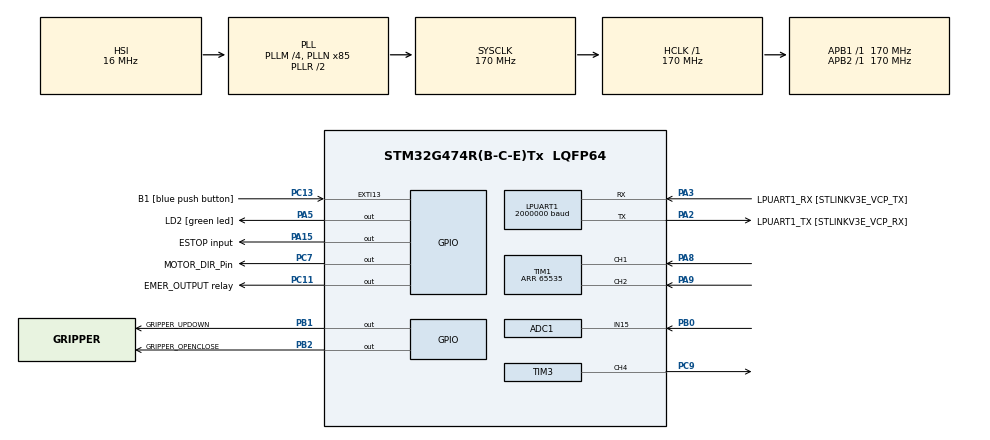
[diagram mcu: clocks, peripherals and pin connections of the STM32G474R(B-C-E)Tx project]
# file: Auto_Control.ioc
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ADC1.Channel-1\#ChannelRegularConversion=ADC_CHANNEL_15
ADC1.NbrOfConversionFlag=1
ADC1.OffsetNumber-1\#ChannelRegularConversion=ADC_OFFSET_NONE
ADC1.Rank-1\#ChannelRegularConversion=1
ADC1.SamplingTime-1\#ChannelRegularConversion=ADC_SAMPLETIME_2CYCLES_5
ADC1.master=1
ARM.CMSIS.5.7.0.CMSISJjCORE=true
ARM.CMSIS.5.7.0.CMSISJjDSP=Library
LPUART1.BaudRate=2000000
Mcu.Family=STM32G4
Mcu.Name=STM32G474R(B-C-E)Tx
Mcu.Package=LQFP64
NVIC.EXTI15_10_IRQn=true\:0\:0\:false\:false\:true\:true\:true\:true
NVIC.PriorityGroup=NVIC_PRIORITYGROUP_4
NVIC.TIM6_DAC_IRQn=true\:0\:0\:false\:false\:true\:true\:true\:true
NVIC.TIM7_DAC_IRQn=true\:0\:0\:false\:false\:true\:true\:true\:true
PA1.Signal=SharedAnalog_PA1
PA13.GPIO_Label=T_SWDIO
PA13.Signal=SYS_JTMS-SWDIO
PA14.GPIO_Label=T_SWCLK
PA14.Signal=SYS_JTCK-SWCLK
PA15.GPIO_Label=ESTOP input
PA15.Signal=GPIO_Output
PA2.GPIO_Label=LPUART1_TX [STLINKV3E_VCP_RX]
PA2.Mode=Asynchronous
PA2.Signal=LPUART1_TX
PA3.GPIO_Label=LPUART1_RX [STLINKV3E_VCP_TX]
PA3.Mode=Asynchronous
PA3.Signal=LPUART1_RX
PA5.GPIO_Label=LD2 [green led]
PA5.Signal=GPIO_Output
PA8.Signal=S_TIM1_CH1
PA9.Signal=S_TIM1_CH2
PB0.Mode=IN15-Single-Ended
PB0.Signal=ADC1_IN15
PB1.GPIO_Label=GRIPPER_UPDOWN
PB1.Signal=GPIO_Output
PB2.GPIO_Label=GRIPPER_OPENCLOSE
PB2.Signal=GPIO_Output
PB3.GPIO_Label=T_SWO
PB3.Signal=SYS_JTDO-SWO
PC11.GPIO_Label=EMER_OUTPUT relay
PC11.Signal=GPIO_Output
PC13.GPIO_Label=B1 [blue push button]
PC13.Signal=GPXTI13
PC14-OSC32_IN.GPIO_Label=RCC_OSC32_IN
PC14-OSC32_IN.Signal=RCC_OSC32_IN
PC15-OSC32_OUT.GPIO_Label=RCC_OSC32_OUT
PC15-OSC32_OUT.Signal=RCC_OSC32_OUT
PC7.GPIO_Label=MOTOR_DIR_Pin
PC7.Signal=GPIO_Output
PC9.Signal=S_TIM3_CH4
PF0-OSC_IN.GPIO_Label=RCC_OSC_IN
PF0-OSC_IN.Signal=RCC_OSC_IN
PF1-OSC_OUT.GPIO_Label=RCC_OSC_OUT
PF1-OSC_OUT.Signal=RCC_OSC_OUT
ProjectManager.HeapSize=0x200
ProjectManager.StackSize=0x400
ProjectManager.TargetToolchain=STM32CubeIDE
RCC.ADC12Freq_Value=170000000
RCC.ADC345Freq_Value=170000000
RCC.AHBFreq_Value=170000000
RCC.APB1Freq_Value=170000000
RCC.APB1TimFreq_Value=170000000
RCC.APB2Freq_Value=170000000
RCC.APB2TimFreq_Value=170000000
RCC.CortexFreq_Value=170000000
RCC.EXTERNAL_CLOCK_VALUE=12288000
RCC.HCLKFreq_Value=170000000
RCC.HSE_VALUE=24000000
RCC.HSI48_VALUE=48000000
RCC.HSI_VALUE=16000000
RCC.LSE_VALUE=32768
RCC.PLLM=RCC_PLLM_DIV4
RCC.PLLN=85
RCC.RTCClockSelection=RCC_RTCCLKSOURCE_LSE
RCC.SYSCLKFreq_VALUE=170000000
RCC.SYSCLKSource=RCC_SYSCLKSOURCE_PLLCLK
RCC.USBFreq_Value=170000000
RCC.VCOOutputFreq_Value=340000000
SH.S_TIM1_CH1.0=TIM1_CH1,Encoder_Interface
SH.S_TIM1_CH2.0=TIM1_CH2,Encoder_Interface
SH.S_TIM3_CH4.0=TIM3_CH4,PWM Generation4 CH4
SH.SharedAnalog_PA1.0=ADC2_IN2
SH.SharedAnalog_PA1.1=ADC1_IN2
TIM1.EncoderMode=TIM_ENCODERMODE_TI12
TIM1.PeriodNoDither=65535
TIM3.Channel-PWM\ Generation4\ CH4=TIM_CHANNEL_4
TIM3.PeriodNoDither=999
TIM3.Prescaler=169
TIM6.PeriodNoDither=999
TIM6.Prescaler=167
TIM7.PeriodNoDither=1999
TIM7.Prescaler=169
VP_ARM.CMSIS_VS_CMSISJjCORE_5.4.0_5.7.0.Mode=CMSISJjCORE
VP_ARM.CMSIS_VS_CMSISJjDSP_1.8.0_5.7.0.Mode=CMSISJjDSP
VP_SYS_VS_DBSignals.Mode=DisableDeadBatterySignals
VP_TIM3_VS_ClockSourceINT.Mode=Internal
VP_TIM6_VS_ClockSourceINT.Mode=Enable_Timer
VP_TIM7_VS_ClockSourceINT.Mode=Enable_Timer
board=NUCLEO-G474RE

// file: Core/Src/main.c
/* USER CODE BEGIN Header */
/**
  ******************************************************************************
  * @file           : main.c
  * @brief          : Main program body
  ******************************************************************************
  * @attention
  *
  * Copyright (c) 2026 STMicroelectronics.
  * All rights reserved.
  *
  * This software is licensed under terms that can be found in the LICENSE file
  * in the root directory of this software component.
  * If no LICENSE file comes with this software, it is provided AS-IS.
  *
  ******************************************************************************
  */
/* USER CODE END Header */
#include "main.h"

/* USER CODE BEGIN Includes */
#include "scurve.h"
#include "encoder.h"
#include "trapezoid.h"
#include "REF_FEEDFORWARD.h"
#include "Kalman4.h"
#include "DistFF.h"
#include <string.h>
#include <math.h>
/* USER CODE END Includes */

/* USER CODE BEGIN PD */
#define LOOP_DT      0.001f    // 1000Hz = 1ms
// max_velocity, max_accel, max_jerk are now volatile floats in Private Variables
// so they can be changed in Live Expressions without reflashing.

// --- Control Mode Constants (set control_mode via Live Expressions) ---
//   1 = Traj FF (open-loop)   — trajectory → RefFF → PWM, no feedback PID
//   2 = Position PID only     — trajectory + position PID → PWM directly (no velocity inner loop)
//   3 = Full cascade          — trajectory + position PID + velocity PID
//   7 = Kalman4 calibration   — direct PWM via kf_cal_pwm + Kalman4 estimation for noise tuning
#define MODE_TRAJ_FF        1
#define MODE_POS_CTRL       2
#define MODE_CASCADE_CTRL   3
#define MODE_KALMAN_CAL     7

// --- Trajectory Type Constants (set traj_type via Live Expressions) ---
//   0 = S-Curve  (jerk-limited, smooth)
//   1 = Trapezoidal  (acceleration-limited, linear ramp)
#define TRAJ_SCURVE      0
#define TRAJ_TRAPEZOID   1

#define DEG_TO_RAD           (3.14159265f / 180.0f) // Degree → radian conversion
#define POS_DT               0.002f                 // 500 Hz position loop (TIM7)
#define TRAJ_DT              0.001f                 // 1000 Hz trajectory generation (TIM6)
#define KF_EXP_COUNT         6                      // number of parallel Kalman instances in Q/R experiment
/* USER CODE END PD */

ADC_HandleTypeDef hadc1;

UART_HandleTypeDef hlpuart1;

TIM_HandleTypeDef htim1;
TIM_HandleTypeDef htim3;
TIM_HandleTypeDef htim6;
TIM_HandleTypeDef htim7;

/* USER CODE BEGIN PV */
SCurve_t        my_scurve;
Trapezoid_t     my_trapezoid;
Encoder_t       my_encoder;
RefFF_t         my_refff;
KalmanFilter4_t my_kf4;
DistFF_t        my_distff;

// --- Trajectory profile limits (Live Expressions — takes effect on next start_move) ---
volatile float max_velocity = 3.0f;   // rad/s   — peak speed of the velocity profile
volatile float max_accel    = 12.56f;   // rad/s²  — max acceleration / deceleration rate
volatile float max_jerk     = 10.0f;   // rad/s³  — S-curve only: rate of accel change

// --- Live Expressions variables ---
// Change these in STM32CubeIDE Live Expressions during debug to switch
// mode or trajectory type without reflashing.
//
//   control_mode : 1 = Traj FF (open-loop),  3 = Full cascade (PID)
//   traj_type    : 0 = S-Curve,   1 = Trapezoidal
volatile uint8_t control_mode      = 3;
volatile uint8_t prev_control_mode = 0xFF;
volatile uint8_t traj_type         = TRAJ_SCURVE;
volatile uint8_t prev_traj_type    = 0xFF;

// Trajectory trigger — set to 1 in Live Expressions to (re)start a move
volatile uint8_t start_move          = 0;

// --- Sequence mode: execute up to 9 preset targets in order ---
volatile float   seq_targets[9]  = {0.0f, 0.0f, 0.0f, 0.0f, 0.0f, 0.0f, 0.0f, 0.0f, 0.0f};
volatile uint8_t seq_count       = 0;    // number of active steps (1-9)
volatile uint8_t seq_enabled     = 0;    // write 1 to start sequence — self-clears when done
volatile uint8_t seq_index       = 0;    // read-only: current step (0-based)
volatile float   seq_step_delay  = 2.0f; // dwell time between steps (s)

// --- Sweep mode: 0 → start → 0 → (start+step) → ... → 0 → stop ---
// Programmatic version of sequence for large step counts.
// Pattern: return to zero between every target, advancing by sweep_step_deg each cycle.
volatile uint8_t sweep_enabled   = 0;      // write 1 to start — self-clears when done
volatile float   sweep_start_deg = 5.0f;   // first non-zero target (deg)
volatile float   sweep_stop_deg  = 360.0f; // last non-zero target (deg)
volatile float   sweep_step_deg  = 5.0f;   // increment per step (deg)
volatile float   sweep_delay_s   = 2.0f;   // dwell time at each position (s)
volatile uint8_t sweep_index     = 0;      // current step index — read-only

// Encoder zero — set to 1 in Live Expressions to zero position at any time
volatile uint8_t zero_encoder        = 0;

// Full state reset — set to 1 to clear ALL runtime state (PIDs, trajectory,
// encoder, commands, observables). Motor stops immediately. Self-clears to 0.
volatile uint8_t reset_all           = 0;

// PID master enable — set to 0 to freeze all PID loops and hold PWM=0.
// Trajectory is paused (does not advance). Set back to 1 to resume control.
// Use start_move=1 after re-enabling to restart the trajectory from scratch.
volatile uint8_t pid_enabled         = 0;

// Target position in DEGREES — type any value here in Live Expressions.
// Changing this automatically starts a new trajectory (no need for start_move).
volatile float   traj_target_deg      = 0.0f;   // target position (deg) — change in Live Expressions
volatile float   prev_traj_target_deg = 0.0f;

// Mode 2 (Position PID only) direct setpoint — no trajectory, just a single degree value.
// Change this in Live Expressions; the position PID tracks it directly.
volatile float   pos_ctrl_target_deg  = 0.0f;

// --- Time-based profile shape parameters (Live Expressions) ---
// S-curve:   t1_seg, t2_seg — ramp shape. t_cruise_seg auto-computed (read-only).
// Trapezoid: t_acc_seg, t_cruise_seg, t_dec_seg — all user-specified (writable).
//            v_peak is back-computed from displacement and times.
//            v_peak is only clamped to max_velocity if it exceeds it.
volatile float   t1_seg            = 0.3f;  // S-curve:   jerk segment duration      (s)
volatile float   t2_seg            = 0.3f;  // S-curve:   const-accel duration       (s)
volatile float   t_acc_seg         = 0.3f;  // Trapezoid: acceleration duration      (s)
volatile float   t_cruise_seg      = 0.5f;  // Trapezoid: cruise duration — writable (s) | S-curve: read-only computed
volatile float   t_dec_seg         = 0.3f;  // Trapezoid: deceleration duration      (s)
// Minimum peak velocity — auto-scales t1/t2 down for short moves so motor
// always ramps fast enough to overcome static friction.  0 = disabled.
volatile float   min_vpeak_rad_s   = 0.5f;  // minimum v_peak (rad/s) — tune up if still jerky

// Telemetry signals — volatile so Live Expressions always reads current RAM value
// UART packet (32 bytes): [0x7E][0x7E][traj_pos][traj_vel][traj_accel][traj_jerk][act_pos][act_vel][kf_vel][0x03][0x03]
//   traj_pos   — absolute trajectory position (rad): traj_start_pos + p_current
//   traj_vel   — trajectory velocity  (rad/s): v_current
//   traj_accel — trajectory accel     (rad/s²): a_current
//   traj_jerk  — trajectory jerk      (rad/s³): j_current  (0 for trapezoid)
//   act_pos    — actual encoder position (rad): my_encoder.position_rad
//   act_vel    — actual encoder velocity (rad/s): my_encoder.velocity_rad_s
//   kf_vel     — Kalman estimated velocity (rad/s): g_kf_velocity
volatile float   g_traj_pos     = 0.0f;  // trajectory absolute position (rad)
volatile float   g_smooth_vel   = 0.0f;  // trajectory velocity          (rad/s)
volatile float   g_smooth_accel = 0.0f;  // trajectory acceleration      (rad/s²)
volatile float   g_jerk         = 0.0f;  // trajectory jerk              (rad/s³)
volatile uint8_t g_traj_active  = 0;     // 1 = trajectory running — written by TIM6 at 1 kHz

// Encoder observables — also in UART packet (act_pos @ byte 18, act_vel @ byte 22)
volatile float g_position_rad   = 0.0f;
volatile float g_velocity_rad_s = 0.0f;
volatile float g_pwm_duty       = 0.0f;

static   uint8_t          tx_buf[76];
volatile uint8_t          tx_pending = 0;

// --- Mode 4: Encoder test — dedicated read-only monitoring variables ---

// --- Motor direction --- set to 1 if actual motion is opposite to trajectory
// Flip in Live Expressions (0 or 1) — takes effect immediately, no reflash needed.
volatile uint8_t motor_dir_inverted = 0;

// --- Emergency output relay (PC11 / EMER_OUTPUT_relay_Pin) ---
// Write 1 to energise the relay, 0 to de-energise.
// Applied every while(1) iteration — no reflash needed.
volatile uint8_t emer_output        = 0;
volatile uint8_t gripper_updown     = 0;   // PB1: 0=down,  1=up
volatile uint8_t gripper_openclose  = 0;   // PB2: 0=close, 1=open

// --- Minimum PWM threshold — overcomes motor static friction (dead zone) ---
// Any non-zero PWM command below this value is raised to this threshold.
// Find your motor's dead zone: increase slowly until the shaft just barely moves.
volatile float min_pwm_threshold = 5.0f;   // % — tune in Live Expressions

// --- PID debug observables (all modes) ---
volatile float ss_error_deg   = 0.0f;  // steady-state position error (degrees)
volatile float ss_error_rad   = 0.0f;  // steady-state position error (radians)
volatile float vel_error_live = 0.0f;  // current velocity error into PID (rad/s)
volatile float i_term_live    = 0.0f;  // current integral accumulator value

// Absolute encoder position captured when a trajectory starts.
// p_current (relative, starts at 0) + traj_start_pos = absolute ideal position.
static float traj_start_pos = 0.0f;

// --- Inter-loop interface: TIM7 (500 Hz) writes, TIM6 (1 kHz) reads ---
volatile float   vel_command      = 0.0f;  // velocity set-point for Modes 3, 5
volatile float   pwm_command      = 0.0f;  // direct PWM for Modes 1, 2, 6
volatile uint8_t hard_stop_active = 0;     // 1 = TIM6 sets PWM=0, skips velocity PID

// --- Reference Feedforward ---
// Set refff_enabled = 1 in Live Expressions to activate.
// V_supply must match the actual bus voltage driving the motor driver.
volatile uint8_t refff_enabled = 1;     // 0 = off, 1 = on
volatile float   V_supply      = 24.0f; // motor bus voltage (V)

// --- Disturbance Feedforward ---
// Uses Kalman4 tau_d estimate to pre-cancel load disturbances.
// distff_tau: filter time constant (s) — same role as in RefFF.
// g_distff_pwm: observe before enabling to check output is sane.
volatile uint8_t distff_enabled = 0;      // 0 = off, 1 = active
volatile float   distff_tau     = 0.02f;  // filter time constant (s)
volatile float   g_distff_pwm  = 0.0f;   // PWM addend from DistFF (%) — read-only

// --- Current sensor — ADC1 IN2 (PA1) ---
// Requires ADC1 IN2 enabled in CubeMX (single or continuous, 12-bit, no DMA).
// Conversion:  I = (adc_raw - current_zero_counts) / current_counts_per_amp
volatile float    current_zero_counts    = 2892.7f; // ADC count at zero current — tune in Live Expressions
volatile float    current_counts_per_amp = 86.57f;  // ADC counts per ampere    — tune in Live Expressions
volatile uint32_t adc_raw_current        = 0;       // raw 12-bit count (0–4095) — read-onlyy
volatile float    g_current_A            = 0.0f;    // measured motor current (A) — read-only

// --- Mode 7: Kalman4 calibration ---
// Set kf_cal_pwm to drive the motor open-loop while Kalman4 estimates the state.
// Tune kf4_sigma_v2 / kf4_r_theta, then reset_all = 1 to reinit with new values.
volatile float   kf_cal_pwm      = 0.0f;   // DC offset PWM command -100..+100 %
volatile uint8_t kf_sine_enabled = 0;      // 0 = direct kf_cal_pwm, 1 = sine wave
volatile float   kf_sine_amp     = 20.0f;  // sine amplitude (%)
volatile float   kf_sine_freq    = 1.0f;   // sine frequency (Hz)
volatile float   kf_sine_dir     = 1.0f;   // +1.0 = normal,  -1.0 = reversed direction
volatile float   kf4_sigma_v2    = 0.01f;   // σ_v² — voltage noise variance: Q = G·σ_v²·Gᵀ → Q[2][2] = σ_v²·(Ts/L)²
volatile float   kf4_r_theta     = 1e-7f;  // R[0] — position measurement noise variance

// --- Kalman4 Q/R Experiment — KF_EXP_COUNT parallel instances running simultaneously ---
// Set kalman_exp_enabled = 1 in Live Expressions to activate.
// When active, the normal 76-byte telemetry is replaced by a 128-byte experiment packet.
// Experiment sets:
//   Index 0-2: fix sigma_v2=0.01, vary r_theta = 1e-4 / 1e-7 / 1e-10
//   Index 3-5: fix r_theta=1e-7,  vary sigma_v2 = 1.0 / 0.01 / 1e-5
// kf_exp_set_id: write 0.0 = R-varied set running; 1.0 = Q-varied set (Simulink label only)
volatile uint8_t kalman_exp_enabled = 0;
volatile float   kf_exp_set_id      = 0.0f;
static   uint8_t kf_exp_tx_pending  = 0;
KalmanFilter4_t  kf_exp[KF_EXP_COUNT];
static float     kf_exp_states[KF_EXP_COUNT][4]; // [pos, vel, current, tau_d] per instance
static uint8_t   kf_exp_tx_buf[128];

static const float kf_exp_sigma_v2[KF_EXP_COUNT] = {
    0.01f, 0.01f,  0.01f,  /* fix Q=0.01, vary R: indices 0-2 */
    1.0f,  0.01f,  1e-5f   /* fix R=1e-7, vary Q: indices 3-5 */
};
static const float kf_exp_r_theta[KF_EXP_COUNT] = {
    1e-4f,  1e-7f,  1e-10f, /* fix Q=0.01, vary R: indices 0-2 */
    1e-7f,  1e-7f,  1e-7f   /* fix R=1e-7, vary Q: indices 3-5 */
};
volatile float   g_kf4_position  = 0.0f;   // Kalman4 estimated position  (rad)   — read-only
volatile float   g_kf4_velocity  = 0.0f;   // Kalman4 estimated velocity  (rad/s) — read-only
volatile float   g_kf4_current   = 0.0f;   // Kalman4 estimated current   (A)     — read-only
volatile float   g_kf4_tau_d_obs = 0.0f;   // Kalman4 estimated τ_d        (N·m)   — read-only
volatile uint8_t use_kf4_vel     = 0;      // 0 = raw encoder velocity, 1 = Kalman4 velocity (both PIDs)
volatile float   g_motor_voltage = 0.0f;   // voltage commanded to motor  (V)     — read-only

// --- Motor parameters — change in Live Expressions, then write apply_motor_params=1 ---
// Both Kalman4 and RefFF will be re-initialised with the new values (position not reset).
volatile float   motor_J_eq  = 0.027f;      // kg·m²    — equivalent inertia (at output shaft)
volatile float   motor_b_eq  = 0.5f;        // N·m·s/r  — equivalent viscous friction
volatile float   motor_N     = 50.0f;       // —         — gear ratio
volatile float   motor_Kt    = 0.00747f;    // N·m/A    — torque constant
volatile float   motor_Ke    = 0.0083f;     // V·s/rad  — back-EMF constant
volatile float   motor_L     = 0.0012794f;  // H         — armature inductance
volatile float   motor_R_arm = 2.8f;        // Ω         — armature resistance
volatile uint8_t apply_motor_params = 0;    // write 1 to apply — self-clears
/* USER CODE END PV */

void SystemClock_Config(void);
static void MX_GPIO_Init(void);
static void MX_LPUART1_UART_Init(void);
static void MX_TIM1_Init(void);
static void MX_TIM6_Init(void);
static void MX_TIM3_Init(void);
static void MX_TIM7_Init(void);
static void MX_ADC1_Init(void);
/* USER CODE BEGIN PFP */
extern float Velocity_PID_Controller(float error);
void Set_Motor_PWM(float pwm_duty);
/* USER CODE END PFP */

/* USER CODE BEGIN 0 */
// --- Velocity PID gains (tunable in Live Expressions) ---
// kp_vel sizing: output = kp_vel × vel_error [rad/s]  →  PWM [%]
// Rule: kp_vel = max_pwm / max_velocity = 100 / 1.57 ≈ 64 gives full PWM at max error.
// Start at 30 (≈ half authority) and tune up until motor tracks trajectory cleanly.
// kd_vel stays 0: derivative amplifies quantization noise at 1 kHz.
float kp_vel = 10.0f;
float ki_vel =  0.01f;
float kd_vel =  0.0f;

float vel_integral    = 0.0f;
float vel_prev_error  = 0.0f;
float max_pwm         = 100.0f;

// --- Saturation experiment limits (Live Expressions — change without reflashing) ---
// vel_sat_rad_s  : caps total vel_command (trajectory + PID correction) into velocity PID.
//                  Default = max_velocity. Lower this to observe velocity saturation effect.
// voltage_sat_pct: caps final PWM output after RefFF + DistFF, before Set_Motor_PWM.
//                  Default = 100%. Lower this to observe voltage saturation effect.
volatile float vel_sat_rad_s    = 53.0f;   // rad/s — velocity command saturation
volatile float voltage_sat_pct  = 100.0f;  // %     — voltage/PWM output saturation

// --- Loop frequency experiment (Live Expressions — no reflash needed) ---
// inner_loop_div: velocity PID fires every N TIM6 ticks (1=1kHz, 2=500Hz, 5=200Hz, 10=100Hz)
// outer_loop_div: position PID fires every N TIM7 ticks (1=500Hz, 2=250Hz, 4=125Hz)
// loop_dt_inner/outer are updated automatically by the ISR — do NOT write them manually.
volatile uint8_t inner_loop_div = 1;
volatile uint8_t outer_loop_div = 1;
volatile float   loop_dt_inner  = 0.001f;   // inner_loop_div × LOOP_DT
volatile float   loop_dt_outer  = 0.002f;   // outer_loop_div × POS_DT

// --- Position PID gains — Modes 3 & 5 output: velocity (rad/s) ---
// kp_position: [rad/s] per [rad] of error. Start at 1.0, tune up carefully.
volatile float kp_position       = 2.0f;
volatile float ki_pos            = 0.5f;
volatile float kd_pos            = 0.01f;
volatile float pos_deadband_deg  = 0.1f;
volatile float vel_deadband_rad_s = 0.3f;   // velocity threshold for hard stop (rad/s)
volatile uint8_t  ss_reached       = 1;      // 1 = position error within pos_deadband_deg
volatile float    ss_final_error_deg = 0.0f; // error captured at the moment hard stop fired
volatile float pos_integral_live = 0.0f;

float pos_integral  = 0.0f;

// --- Anti-windup enable flags (toggle in Live Expressions — no reflash needed) ---
// 1 = clamp accumulator (protected), 0 = free accumulation (windup scenario)
volatile uint8_t vel_antiwindup_en = 1;
volatile uint8_t pos_antiwindup_en = 1;

float Velocity_PID_Controller(float error) {
    // Proportional
    float p_out = kp_vel * error;

    // Integral with proper anti-windup:
    // Clamp the ACCUMULATOR itself so i_out can never exceed max_pwm.
    // The old approach only clamped i_out at output but let vel_integral
    // grow without bound — causing the motor to keep running after trajectory ends.
    vel_integral += error * loop_dt_inner;
    if (vel_antiwindup_en) {
        float max_integral = (ki_vel > 0.0f) ? (max_pwm / ki_vel) : 0.0f;
        if (vel_integral >  max_integral) vel_integral =  max_integral;
        if (vel_integral < -max_integral) vel_integral = -max_integral;
    }
    float i_out = ki_vel * vel_integral;

    // Derivative
    float derivative = (error - vel_prev_error) / loop_dt_inner;
    float d_out      = kd_vel * derivative;
    vel_prev_error   = error;

    // Expose internals for Live Expressions debugging
    i_term_live = vel_integral;

    // Total output — clamped to PWM limits
    float output = p_out + i_out + d_out;
    if (output >  max_pwm) output =  max_pwm;
    if (output < -max_pwm) output = -max_pwm;

    return output;
}

void Velocity_PID_Reset(void) {
    vel_integral   = 0.0f;
    vel_prev_error = 0.0f;
}

/* Position PID controller.
 *   pos_error    : target_pos − actual_pos  (radians)
 *   vel_feedback : filtered actual velocity  (rad/s)
 *   returns      : velocity command (rad/s) for Modes 3 & 5
 *                  or PWM duty (%) for Mode 2 — caller applies limits.
 *
 * Derivative term uses −velocity instead of Δerror/dt.
 * Reason: d(pos_error)/dt = −d(actual)/dt = −velocity.
 * Using measured velocity is far less noisy than differencing position error. */
float Position_PID_Controller(float pos_error, float vel_feedback) {
    float p_out = kp_position * pos_error;

    // Integral with anti-windup — clamp accumulator so i_out ≤ max_velocity
    pos_integral += pos_error * loop_dt_outer;
    if (pos_antiwindup_en) {
        float max_pos_int = (ki_pos > 0.0f) ? (max_velocity / ki_pos) : 0.0f;
        if (pos_integral >  max_pos_int) pos_integral =  max_pos_int;
        if (pos_integral < -max_pos_int) pos_integral = -max_pos_int;
    }
    float i_out = ki_pos * pos_integral;
    pos_integral_live = pos_integral;

    // Derivative: negate velocity (= derivative of position error)
    float d_out = -kd_pos * vel_feedback;

    return p_out + i_out + d_out;
}

void Position_PID_Reset(void) {
    pos_integral      = 0.0f;
    pos_integral_live = 0.0f;
}

static void Pack_Telemetry(void) {
    // 72-byte packet:
    //  [0x7E][0x7E]
    //  [2 ] traj_pos     4B  float   trajectory ideal position   (rad)
    //  [6 ] traj_vel     4B  float   trajectory velocity         (rad/s)
    //  [10] traj_accel   4B  float   trajectory acceleration     (rad/s²)
    //  [14] traj_jerk    4B  float   trajectory jerk             (rad/s³)
    //  [18] act_pos      4B  float   actual encoder position     (rad)
    //  [22] act_vel      4B  float   actual encoder velocity     (rad/s)
    //  [26] kf_vel       4B  float   Kalman estimated velocity   (rad/s)
    //  [30] kf_pos       4B  float   Kalman estimated position   (rad)
    //  [34] ss_error     4B  float   steady-state position error (rad)
    //  [38] current      4B  float   measured motor current      (A)
    //  [42] kf4_pos      4B  float   Kalman4 estimated position  (rad)
    //  [46] kf4_vel      4B  float   Kalman4 estimated velocity  (rad/s)
    //  [50] kf4_current  4B  float   Kalman4 estimated current   (A)
    //  [54] kf4_tau_d    4B  float   Kalman4 disturbance torque  (N·m)
    //  [58] voltage      4B  float   motor commanded voltage     (V)
    //  [62] adc_raw      4B  uint32  raw ADC count               (0–4095)
    //  [66] i_term_live       4B  float   velocity integrator accumulator
    //  [70] pos_integral_live 4B  float   position integrator accumulator
    //  [74][0x03][0x03]
    tx_buf[0] = 0x7E;
    tx_buf[1] = 0x7E;
    memcpy(&tx_buf[2],  (const void *)&g_traj_pos,        4);
    memcpy(&tx_buf[6],  (const void *)&g_smooth_vel,      4);
    memcpy(&tx_buf[10], (const void *)&g_smooth_accel,    4);
    memcpy(&tx_buf[14], (const void *)&g_jerk,            4);
    memcpy(&tx_buf[18], (const void *)&g_position_rad,    4);
    memcpy(&tx_buf[22], (const void *)&g_velocity_rad_s,  4);
    memcpy(&tx_buf[26], (const void *)&g_kf4_velocity,    4);
    memcpy(&tx_buf[30], (const void *)&g_kf4_position,    4);
    memcpy(&tx_buf[34], (const void *)&ss_error_rad,      4);
    memcpy(&tx_buf[38], (const void *)&g_current_A,       4);
    memcpy(&tx_buf[42], (const void *)&g_kf4_position,    4);
    memcpy(&tx_buf[46], (const void *)&g_kf4_velocity,    4);
    memcpy(&tx_buf[50], (const void *)&g_kf4_current,     4);
    memcpy(&tx_buf[54], (const void *)&g_kf4_tau_d_obs,   4);
    memcpy(&tx_buf[58], (const void *)&g_motor_voltage,   4);
    memcpy(&tx_buf[62], (const void *)&adc_raw_current,   4);
    memcpy(&tx_buf[66], (const void *)&i_term_live,       4);
    memcpy(&tx_buf[70], (const void *)&pos_integral_live, 4);
    tx_buf[74] = 0x03;
    tx_buf[75] = 0x03;
}

static void KalmanExp_Init(void) {
    for (int n = 0; n < KF_EXP_COUNT; n++) {
        Kalman4_Init(&kf_exp[n],
                     my_encoder.position_rad, 0.0f, 0.0f,
                     LOOP_DT,
                     motor_J_eq, motor_b_eq, motor_N, motor_Kt, motor_Ke,
                     motor_L,    motor_R_arm,
                     kf_exp_sigma_v2[n], kf_exp_r_theta[n]);
    }
}

static void Pack_KalmanExp_Telemetry(void) {
    // 128-byte Kalman experiment packet:
    //  [0-1]    0x7E 0x7E  header (same as normal packet — Waijung uses same framing)
    //  [2 ]     ref_pos     4B  float  trajectory reference position  (rad)
    //  [6 ]     ref_vel     4B  float  trajectory reference velocity  (rad/s)
    //  [10]     real_pos    4B  float  encoder position               (rad)
    //  [14]     real_vel    4B  float  encoder velocity               (rad/s)
    //  [18]     current_A   4B  float  motor current                  (A)
    //  [22]     voltage     4B  float  motor voltage                  (V)
    //  [26]     set_id      4B  float  0=vary-R experiment, 1=vary-Q  (label)
    //  [30..45]  kf[0]  pos, vel, current, tau_d  (4×4B = 16B)
    //  [46..61]  kf[1]  pos, vel, current, tau_d
    //  [62..77]  kf[2]  pos, vel, current, tau_d
    //  [78..93]  kf[3]  pos, vel, current, tau_d
    //  [94..109] kf[4]  pos, vel, current, tau_d
    //  [110..125]kf[5]  pos, vel, current, tau_d
    //  [126][127] 0x03 0x03  footer
    kf_exp_tx_buf[0] = 0x7E;
    kf_exp_tx_buf[1] = 0x7E;
    memcpy(&kf_exp_tx_buf[2],  (const void *)&g_traj_pos,        4);
    memcpy(&kf_exp_tx_buf[6],  (const void *)&g_smooth_vel,      4);
    memcpy(&kf_exp_tx_buf[10], (const void *)&g_position_rad,    4);
    memcpy(&kf_exp_tx_buf[14], (const void *)&g_velocity_rad_s,  4);
    memcpy(&kf_exp_tx_buf[18], (const void *)&g_current_A,       4);
    memcpy(&kf_exp_tx_buf[22], (const void *)&g_motor_voltage,   4);
    memcpy(&kf_exp_tx_buf[26], (const void *)&kf_exp_set_id,     4);
    for (int n = 0; n < KF_EXP_COUNT; n++) {
        uint16_t off = (uint16_t)(30 + n * 16);
        memcpy(&kf_exp_tx_buf[off],      &kf_exp_states[n][0], 4);
        memcpy(&kf_exp_tx_buf[off +  4], &kf_exp_states[n][1], 4);
        memcpy(&kf_exp_tx_buf[off +  8], &kf_exp_states[n][2], 4);
        memcpy(&kf_exp_tx_buf[off + 12], &kf_exp_states[n][3], 4);
    }
    kf_exp_tx_buf[126] = 0x03;
    kf_exp_tx_buf[127] = 0x03;
}

/* USER CODE END 0 */

int main(void)
{

  /* MCU Configuration--------------------------------------------------------*/

  /* Reset of all peripherals, Initializes the Flash interface and the Systick. */
  HAL_Init();

  /* Configure the system clock */
  SystemClock_Config();

  /* Initialize all configured peripherals */
  MX_GPIO_Init();
  MX_LPUART1_UART_Init();
  MX_TIM1_Init();
  MX_TIM6_Init();
  MX_TIM3_Init();
  MX_TIM7_Init();
  MX_ADC1_Init();
  /* USER CODE BEGIN 2 */
  // 1. Initialize trajectory and profile math (POS_DT: trajectory runs in 500 Hz TIM7 loop)
      SCurve_Init(&my_scurve, max_velocity, max_accel, max_jerk, TRAJ_DT);
      Trapezoid_Init(&my_trapezoid, max_velocity, max_accel, TRAJ_DT);

      // Reference feedforward — fill in your motor parameters before enabling.
      // refff_enabled = 0 at startup; set to 1 in Live Expressions to activate.
      RefFF_Init(&my_refff,
                 /* J_eq  */ motor_J_eq,
                 /* L     */ motor_L,
                 /* R     */ motor_R_arm,
                 /* b_eq  */ motor_b_eq,
                 /* N     */ motor_N,
                 /* Kt    */ motor_Kt,
                 /* Ke    */ motor_Ke,
                 /* tau   */ 0.02f,
                 /* Ts    */ LOOP_DT
      );

      DistFF_Init(&my_distff,
                  /* L   */ motor_L,
                  /* R   */ motor_R_arm,
                  /* N   */ motor_N,
                  /* Kt  */ motor_Kt,
                  /* tau */ distff_tau,
                  /* Ts  */ LOOP_DT);

      // Kalman4 — 4-state motor filter (position-only measurement, no current sensor).
      // Motor parameters match RefFF_Init above. Tune kf4_* noise params in Live Expressions,
      // then set reset_all = 1 to reinitialise with the new values.
      Kalman4_Init(&my_kf4,
                   /* theta0, omega0, i0 */ 0.0f, 0.0f, 0.0f,
                   /* Ts     */ LOOP_DT,
                   /* J_eq   */ motor_J_eq,
                   /* b_eq   */ motor_b_eq,
                   /* N      */ motor_N,
                   /* Kt     */ motor_Kt,
                   /* Ke     */ motor_Ke,
                   /* L      */ motor_L,
                   /* R_arm  */ motor_R_arm,
                   /* sigma_v2  */ kf4_sigma_v2,
                   /* r_theta   */ kf4_r_theta);
      KalmanExp_Init();

      // 2. Start TIM1 encoder, zero its counter, THEN init encoder struct.
      //    Order matters: counter must be zeroed before Encoder_Init reads
      //    last_counter_value = 0, so the first delta is always 0.
      HAL_TIM_Encoder_Start(&htim1, TIM_CHANNEL_ALL);
      __HAL_TIM_SET_COUNTER(&htim1, 0);
      Encoder_Init(&my_encoder, LOOP_DT);

      // 3. Start TIM3 PWM output
      HAL_TIM_PWM_Start(&htim3, TIM_CHANNEL_4);

      // 4. Start TIM7 (500 Hz position loop) then TIM6 (1 kHz velocity loop)
      MX_TIM7_Init();
      HAL_TIM_Base_Start_IT(&htim7);
      HAL_TIM_Base_Start_IT(&htim6);

      // 5. ADC1 current sensor (PA1 / IN2) — first conversion started by ISR.
  /* USER CODE END 2 */

  /* Infinite loop */
  while (1)
  {

    /* USER CODE BEGIN 3 */
      if (kf_exp_tx_pending) {
          kf_exp_tx_pending = 0;
          HAL_UART_Transmit(&hlpuart1, kf_exp_tx_buf, sizeof(kf_exp_tx_buf), 5);
      } else if (tx_pending) {
          tx_pending = 0;
          HAL_UART_Transmit(&hlpuart1, tx_buf, sizeof(tx_buf), 2);
      }
      HAL_GPIO_WritePin(EMER_OUTPUT_relay_GPIO_Port, EMER_OUTPUT_relay_Pin,
                        emer_output ? GPIO_PIN_SET : GPIO_PIN_RESET);
      HAL_GPIO_WritePin(GRIPPER_UPDOWN_GPIO_Port, GRIPPER_UPDOWN_Pin,
                        gripper_updown    ? GPIO_PIN_SET : GPIO_PIN_RESET);
      HAL_GPIO_WritePin(GRIPPER_OPENCLOSE_GPIO_Port, GRIPPER_OPENCLOSE_Pin,
                        gripper_openclose ? GPIO_PIN_SET : GPIO_PIN_RESET);
  }
  /* USER CODE END 3 */
}

void SystemClock_Config(void)
{
  RCC_OscInitTypeDef RCC_OscInitStruct = {0};
  RCC_ClkInitTypeDef RCC_ClkInitStruct = {0};

  /** Configure the main internal regulator output voltage
  */
  HAL_PWREx_ControlVoltageScaling(PWR_REGULATOR_VOLTAGE_SCALE1_BOOST);

  /** Initializes the RCC Oscillators according to the specified parameters
  * in the RCC_OscInitTypeDef structure.
  */
  RCC_OscInitStruct.OscillatorType = RCC_OSCILLATORTYPE_HSI;
  RCC_OscInitStruct.HSIState = RCC_HSI_ON;
  RCC_OscInitStruct.HSICalibrationValue = RCC_HSICALIBRATION_DEFAULT;
  RCC_OscInitStruct.PLL.PLLState = RCC_PLL_ON;
  RCC_OscInitStruct.PLL.PLLSource = RCC_PLLSOURCE_HSI;
  RCC_OscInitStruct.PLL.PLLM = RCC_PLLM_DIV4;
  RCC_OscInitStruct.PLL.PLLN = 85;
  RCC_OscInitStruct.PLL.PLLP = RCC_PLLP_DIV2;
  RCC_OscInitStruct.PLL.PLLQ = RCC_PLLQ_DIV2;
  RCC_OscInitStruct.PLL.PLLR = RCC_PLLR_DIV2;
  if (HAL_RCC_OscConfig(&RCC_OscInitStruct) != HAL_OK)
  {
    Error_Handler();
  }

  /** Initializes the CPU, AHB and APB buses clocks
  */
  RCC_ClkInitStruct.ClockType = RCC_CLOCKTYPE_HCLK|RCC_CLOCKTYPE_SYSCLK
                              |RCC_CLOCKTYPE_PCLK1|RCC_CLOCKTYPE_PCLK2;
  RCC_ClkInitStruct.SYSCLKSource = RCC_SYSCLKSOURCE_PLLCLK;
  RCC_ClkInitStruct.AHBCLKDivider = RCC_SYSCLK_DIV1;
  RCC_ClkInitStruct.APB1CLKDivider = RCC_HCLK_DIV1;
  RCC_ClkInitStruct.APB2CLKDivider = RCC_HCLK_DIV1;

  if (HAL_RCC_ClockConfig(&RCC_ClkInitStruct, FLASH_LATENCY_4) != HAL_OK)
  {
    Error_Handler();
  }
}

static void MX_ADC1_Init(void)
{

  ADC_MultiModeTypeDef multimode = {0};
  ADC_ChannelConfTypeDef sConfig = {0};

  /** Common config
  */
  hadc1.Instance = ADC1;
  hadc1.Init.ClockPrescaler = ADC_CLOCK_SYNC_PCLK_DIV4;
  hadc1.Init.Resolution = ADC_RESOLUTION_12B;
  hadc1.Init.DataAlign = ADC_DATAALIGN_RIGHT;
  hadc1.Init.GainCompensation = 0;
  hadc1.Init.ScanConvMode = ADC_SCAN_DISABLE;
  hadc1.Init.EOCSelection = ADC_EOC_SINGLE_CONV;
  hadc1.Init.LowPowerAutoWait = DISABLE;
  hadc1.Init.ContinuousConvMode = DISABLE;
  hadc1.Init.NbrOfConversion = 1;
  hadc1.Init.DiscontinuousConvMode = DISABLE;
  hadc1.Init.ExternalTrigConv = ADC_SOFTWARE_START;
  hadc1.Init.ExternalTrigConvEdge = ADC_EXTERNALTRIGCONVEDGE_NONE;
  hadc1.Init.DMAContinuousRequests = DISABLE;
  hadc1.Init.Overrun = ADC_OVR_DATA_PRESERVED;
  hadc1.Init.OversamplingMode = DISABLE;
  if (HAL_ADC_Init(&hadc1) != HAL_OK)
  {
    Error_Handler();
  }

  /** Configure the ADC multi-mode
  */
  multimode.Mode = ADC_MODE_INDEPENDENT;
  if (HAL_ADCEx_MultiModeConfigChannel(&hadc1, &multimode) != HAL_OK)
  {
    Error_Handler();
  }

  /** Configure Regular Channel
  */
  sConfig.Channel = ADC_CHANNEL_15;
  sConfig.Rank = ADC_REGULAR_RANK_1;
  sConfig.SamplingTime = ADC_SAMPLETIME_2CYCLES_5;
  sConfig.SingleDiff = ADC_SINGLE_ENDED;
  sConfig.OffsetNumber = ADC_OFFSET_NONE;
  sConfig.Offset = 0;
  if (HAL_ADC_ConfigChannel(&hadc1, &sConfig) != HAL_OK)
  {
    Error_Handler();
  }

}

static void MX_LPUART1_UART_Init(void)
{

  hlpuart1.Instance = LPUART1;
  hlpuart1.Init.BaudRate = 2000000;
  hlpuart1.Init.WordLength = UART_WORDLENGTH_8B;
  hlpuart1.Init.StopBits = UART_STOPBITS_1;
  hlpuart1.Init.Parity = UART_PARITY_NONE;
  hlpuart1.Init.Mode = UART_MODE_TX_RX;
  hlpuart1.Init.HwFlowCtl = UART_HWCONTROL_NONE;
  hlpuart1.Init.OneBitSampling = UART_ONE_BIT_SAMPLE_DISABLE;
  hlpuart1.Init.ClockPrescaler = UART_PRESCALER_DIV1;
  hlpuart1.AdvancedInit.AdvFeatureInit = UART_ADVFEATURE_NO_INIT;
  if (HAL_UART_Init(&hlpuart1) != HAL_OK)
  {
    Error_Handler();
  }
  if (HAL_UARTEx_SetTxFifoThreshold(&hlpuart1, UART_TXFIFO_THRESHOLD_1_8) != HAL_OK)
  {
    Error_Handler();
  }
  if (HAL_UARTEx_SetRxFifoThreshold(&hlpuart1, UART_RXFIFO_THRESHOLD_1_8) != HAL_OK)
  {
    Error_Handler();
  }
  if (HAL_UARTEx_DisableFifoMode(&hlpuart1) != HAL_OK)
  {
    Error_Handler();
  }

}

static void MX_TIM1_Init(void)
{

  TIM_Encoder_InitTypeDef sConfig = {0};
  TIM_MasterConfigTypeDef sMasterConfig = {0};

  htim1.Instance = TIM1;
  htim1.Init.Prescaler = 0;
  htim1.Init.CounterMode = TIM_COUNTERMODE_UP;
  htim1.Init.Period = 65535;
  htim1.Init.ClockDivision = TIM_CLOCKDIVISION_DIV1;
  htim1.Init.RepetitionCounter = 0;
  htim1.Init.AutoReloadPreload = TIM_AUTORELOAD_PRELOAD_DISABLE;
  sConfig.EncoderMode = TIM_ENCODERMODE_TI12;
  sConfig.IC1Polarity = TIM_ICPOLARITY_RISING;
  sConfig.IC1Selection = TIM_ICSELECTION_DIRECTTI;
  sConfig.IC1Prescaler = TIM_ICPSC_DIV1;
  sConfig.IC1Filter = 0;
  sConfig.IC2Polarity = TIM_ICPOLARITY_RISING;
  sConfig.IC2Selection = TIM_ICSELECTION_DIRECTTI;
  sConfig.IC2Prescaler = TIM_ICPSC_DIV1;
  sConfig.IC2Filter = 0;
  if (HAL_TIM_Encoder_Init(&htim1, &sConfig) != HAL_OK)
  {
    Error_Handler();
  }
  sMasterConfig.MasterOutputTrigger = TIM_TRGO_RESET;
  sMasterConfig.MasterOutputTrigger2 = TIM_TRGO2_RESET;
  sMasterConfig.MasterSlaveMode = TIM_MASTERSLAVEMODE_DISABLE;
  if (HAL_TIMEx_MasterConfigSynchronization(&htim1, &sMasterConfig) != HAL_OK)
  {
    Error_Handler();
  }

}

static void MX_TIM3_Init(void)
{

  TIM_ClockConfigTypeDef sClockSourceConfig = {0};
  TIM_MasterConfigTypeDef sMasterConfig = {0};
  TIM_OC_InitTypeDef sConfigOC = {0};

  htim3.Instance = TIM3;
  htim3.Init.Prescaler = 169;
  htim3.Init.CounterMode = TIM_COUNTERMODE_UP;
  htim3.Init.Period = 999;
  htim3.Init.ClockDivision = TIM_CLOCKDIVISION_DIV1;
  htim3.Init.AutoReloadPreload = TIM_AUTORELOAD_PRELOAD_DISABLE;
  if (HAL_TIM_Base_Init(&htim3) != HAL_OK)
  {
    Error_Handler();
  }
  sClockSourceConfig.ClockSource = TIM_CLOCKSOURCE_INTERNAL;
  if (HAL_TIM_ConfigClockSource(&htim3, &sClockSourceConfig) != HAL_OK)
  {
    Error_Handler();
  }
  if (HAL_TIM_PWM_Init(&htim3) != HAL_OK)
  {
    Error_Handler();
  }
  sMasterConfig.MasterOutputTrigger = TIM_TRGO_RESET;
  sMasterConfig.MasterSlaveMode = TIM_MASTERSLAVEMODE_DISABLE;
  if (HAL_TIMEx_MasterConfigSynchronization(&htim3, &sMasterConfig) != HAL_OK)
  {
    Error_Handler();
  }
  sConfigOC.OCMode = TIM_OCMODE_PWM1;
  sConfigOC.Pulse = 0;
  sConfigOC.OCPolarity = TIM_OCPOLARITY_HIGH;
  sConfigOC.OCFastMode = TIM_OCFAST_DISABLE;
  if (HAL_TIM_PWM_ConfigChannel(&htim3, &sConfigOC, TIM_CHANNEL_4) != HAL_OK)
  {
    Error_Handler();
  }
  HAL_TIM_MspPostInit(&htim3);

}

static void MX_TIM6_Init(void)
{

  TIM_MasterConfigTypeDef sMasterConfig = {0};

  htim6.Instance = TIM6;
  htim6.Init.Prescaler = 167;
  htim6.Init.CounterMode = TIM_COUNTERMODE_UP;
  htim6.Init.Period = 999;
  htim6.Init.AutoReloadPreload = TIM_AUTORELOAD_PRELOAD_DISABLE;
  if (HAL_TIM_Base_Init(&htim6) != HAL_OK)
  {
    Error_Handler();
  }
  sMasterConfig.MasterOutputTrigger = TIM_TRGO_RESET;
  sMasterConfig.MasterSlaveMode = TIM_MASTERSLAVEMODE_DISABLE;
  if (HAL_TIMEx_MasterConfigSynchronization(&htim6, &sMasterConfig) != HAL_OK)
  {
    Error_Handler();
  }

}

static void MX_TIM7_Init(void)
{

  TIM_MasterConfigTypeDef sMasterConfig = {0};

  htim7.Instance = TIM7;
  htim7.Init.Prescaler = 169;
  htim7.Init.CounterMode = TIM_COUNTERMODE_UP;
  htim7.Init.Period = 1999;
  htim7.Init.AutoReloadPreload = TIM_AUTORELOAD_PRELOAD_DISABLE;
  if (HAL_TIM_Base_Init(&htim7) != HAL_OK)
  {
    Error_Handler();
  }
  sMasterConfig.MasterOutputTrigger = TIM_TRGO_RESET;
  sMasterConfig.MasterSlaveMode = TIM_MASTERSLAVEMODE_DISABLE;
  if (HAL_TIMEx_MasterConfigSynchronization(&htim7, &sMasterConfig) != HAL_OK)
  {
    Error_Handler();
  }

}

static void MX_GPIO_Init(void)
{
  GPIO_InitTypeDef GPIO_InitStruct = {0};

  /* GPIO Ports Clock Enable */
  __HAL_RCC_GPIOC_CLK_ENABLE();
  __HAL_RCC_GPIOF_CLK_ENABLE();
  __HAL_RCC_GPIOA_CLK_ENABLE();
  __HAL_RCC_GPIOB_CLK_ENABLE();

  /*Configure GPIO pin Output Level */
  HAL_GPIO_WritePin(GPIOA, LD2_Pin|ESTOP_input_Pin, GPIO_PIN_RESET);

  /*Configure GPIO pin Output Level */
  HAL_GPIO_WritePin(GPIOB, GRIPPER_UPDOWN_Pin|GRIPPER_OPENCLOSE_Pin, GPIO_PIN_RESET);

  /*Configure GPIO pin Output Level */
  HAL_GPIO_WritePin(GPIOC, MOTOR_DIR_Pin_Pin|EMER_OUTPUT_relay_Pin, GPIO_PIN_RESET);

  /*Configure GPIO pin : B1_Pin */
  GPIO_InitStruct.Pin = B1_Pin;
  GPIO_InitStruct.Mode = GPIO_MODE_IT_RISING;
  GPIO_InitStruct.Pull = GPIO_NOPULL;
  HAL_GPIO_Init(B1_GPIO_Port, &GPIO_InitStruct);

  /*Configure GPIO pin : PA1 */
  GPIO_InitStruct.Pin = GPIO_PIN_1;
  GPIO_InitStruct.Mode = GPIO_MODE_ANALOG;
  GPIO_InitStruct.Pull = GPIO_NOPULL;
  HAL_GPIO_Init(GPIOA, &GPIO_InitStruct);

  /*Configure GPIO pins : LD2_Pin ESTOP_input_Pin */
  GPIO_InitStruct.Pin = LD2_Pin|ESTOP_input_Pin;
  GPIO_InitStruct.Mode = GPIO_MODE_OUTPUT_PP;
  GPIO_InitStruct.Pull = GPIO_NOPULL;
  GPIO_InitStruct.Speed = GPIO_SPEED_FREQ_LOW;
  HAL_GPIO_Init(GPIOA, &GPIO_InitStruct);

  /*Configure GPIO pins : GRIPPER_UPDOWN_Pin GRIPPER_OPENCLOSE_Pin */
  GPIO_InitStruct.Pin = GRIPPER_UPDOWN_Pin|GRIPPER_OPENCLOSE_Pin;
  GPIO_InitStruct.Mode = GPIO_MODE_OUTPUT_PP;
  GPIO_InitStruct.Pull = GPIO_NOPULL;
  GPIO_InitStruct.Speed = GPIO_SPEED_FREQ_LOW;
  HAL_GPIO_Init(GPIOB, &GPIO_InitStruct);

  /*Configure GPIO pins : MOTOR_DIR_Pin_Pin EMER_OUTPUT_relay_Pin */
  GPIO_InitStruct.Pin = MOTOR_DIR_Pin_Pin|EMER_OUTPUT_relay_Pin;
  GPIO_InitStruct.Mode = GPIO_MODE_OUTPUT_PP;
  GPIO_InitStruct.Pull = GPIO_NOPULL;
  GPIO_InitStruct.Speed = GPIO_SPEED_FREQ_LOW;
  HAL_GPIO_Init(GPIOC, &GPIO_InitStruct);

  /* EXTI interrupt init*/
  HAL_NVIC_SetPriority(EXTI15_10_IRQn, 0, 0);
  HAL_NVIC_EnableIRQ(EXTI15_10_IRQn);

}

/* USER CODE BEGIN 4 */
static uint8_t prev_traj_active_m3 = 0;   // Mode 3: detects trajectory completion in TIM7
static uint8_t prev_pid_enabled    = 0;   // rising-edge detector for pid_enabled
static uint8_t  seq_was_enabled     = 0;       // sequence rising-edge detector
static uint8_t  seq_step_done       = 0;       // 1 = step settled, counting delay
static uint32_t seq_delay_counter   = 0;       // TIM7 ticks remaining in inter-step delay
static uint8_t  sweep_was_enabled   = 0;       // sweep rising-edge detector
static uint8_t  sweep_state         = 0;       // 0 = heading to target, 1 = heading to zero
static uint8_t  sweep_step_done     = 0;       // 1 = step settled, counting delay
static uint32_t sweep_delay_counter = 0;       // TIM7 ticks remaining in inter-step delay
static float   kf_sine_phase       = 0.0f; // Mode 7: sine wave phase accumulator (rad)

// --- NEW PWM OUTPUT FUNCTION ---
// Assumes pwm_duty comes from the PID as a float between -100.0f and 100.0f
void Set_Motor_PWM(float pwm_duty) {

    // 0. Apply direction inversion if motor wiring is physically reversed
    if (motor_dir_inverted) pwm_duty = -pwm_duty;

    // 1. Determine direction and set the GPIO pin
    if (pwm_duty >= 0.0f) {
        // Forward
        HAL_GPIO_WritePin(MOTOR_DIR_Pin_GPIO_Port, MOTOR_DIR_Pin_Pin, GPIO_PIN_SET);
    } else {
        // Reverse
        HAL_GPIO_WritePin(MOTOR_DIR_Pin_GPIO_Port, MOTOR_DIR_Pin_Pin, GPIO_PIN_RESET);
        // Make duty cycle positive for the timer
        pwm_duty = -pwm_duty;
    }

    // 2. Apply minimum threshold to overcome motor dead zone / static friction.
    //    Only applies when a non-zero PWM was requested (pwm_duty is positive here
    //    because the sign was handled above). Set_Motor_PWM(0) stays at zero.
    if (pwm_duty > 0.0f && pwm_duty < min_pwm_threshold) {
        pwm_duty = min_pwm_threshold;
    }

    // 3. Clamp duty cycle to absolute max (100.0%) to prevent overflow
    if (pwm_duty > 100.0f) {
        pwm_duty = 100.0f;
    }

    // 3. Map the percentage (0-100) to your Timer's ARR value (0-1000)
    // Formula: (Duty % / 100) * ARR
    uint32_t compare_value = (uint32_t)((pwm_duty / 100.0f) * 1000.0f);

    // 4. Write directly to the hardware register for zero latency
    __HAL_TIM_SET_COMPARE(&htim3, TIM_CHANNEL_4, compare_value);
}

/* Internal helper: (re)start whichever trajectory generator is active.
 * displacement = target_rad - current_pos  (actual distance to travel).
 *
 * Always uses time-based profile. t_cruise is computed automatically so that
 * v_peak = max_velocity. For short moves where |displacement| < max_velocity *
 * accel_time, t_cruise clamps to 0 and v_peak < max_velocity (triangle/parabola). */
static void Start_Trajectory(float displacement) {
    traj_start_pos = my_encoder.position_rad;
    float abs_disp = fabsf(displacement);

    if (traj_type == TRAJ_TRAPEZOID) {
        Trapezoid_Init(&my_trapezoid, max_velocity, max_accel, TRAJ_DT);
        // t_acc_seg, t_cruise_seg, t_dec_seg are user-specified in Live Expressions.
        // v_peak = |d| / (t_acc/2 + t_cruise + t_dec/2) — back-computed from times.
        // v_peak clamped to max_velocity only if it exceeds it; t_cruise unchanged.
        Trapezoid_SetTarget_ByTime(&my_trapezoid, displacement,
                                   t_acc_seg, t_cruise_seg, t_dec_seg);
        // Write back actual cruise time — T2-T1 may be larger than t_cruise_seg
        // when v_peak was clamped to max_velocity to cover the full displacement.
        t_cruise_seg = my_trapezoid.T2 - my_trapezoid.T1;
    } else {
        SCurve_Init(&my_scurve, max_velocity, max_accel, max_jerk, TRAJ_DT);
        // Auto-scale t1/t2 for short moves: keep v_peak >= min_vpeak_rad_s so the
        // motor always ramps fast enough to overcome static friction.
        float eff_t1  = t1_seg;
        float eff_t2  = t2_seg;
        float t_acc   = 2.0f * eff_t1 + eff_t2;
        if (min_vpeak_rad_s > 0.0f && t_acc > 0.0f) {
            float implied_vpeak = abs_disp / t_acc;
            if (implied_vpeak < min_vpeak_rad_s) {
                float scale = implied_vpeak / min_vpeak_rad_s;  // < 1
                eff_t1 = t1_seg * scale;
                eff_t2 = t2_seg * scale;
                if (eff_t1 < 0.005f) eff_t1 = 0.005f;  // floor at 5 ms
            }
        }
        // v_peak = d / (2*t1 + t2 + t_cruise)  →  t_cruise = d/v_max - 2*t1 - t2
        float t_cruise = (max_velocity > 0.0f)
                         ? (abs_disp / max_velocity - 2.0f * eff_t1 - eff_t2)
                         : 0.0f;
        if (t_cruise < 0.0f) t_cruise = 0.0f;
        t_cruise_seg = t_cruise;
        SCurve_SetTarget_ByTime(&my_scurve, displacement, eff_t1, eff_t2, t_cruise);
    }
    Velocity_PID_Reset();
    Position_PID_Reset();
}

void HAL_TIM_PeriodElapsedCallback(TIM_HandleTypeDef *htim) {

    // =========================================================================
    // TIM6 — 1 kHz INNER LOOP: encoder update + velocity PID + PWM output
    // =========================================================================
    if (htim->Instance == TIM6) {

        uint16_t raw_timer = __HAL_TIM_GET_COUNTER(&htim1);
        Encoder_Update(&my_encoder, raw_timer);

        HAL_ADC_Stop(&hadc1);
        HAL_ADC_Start(&hadc1);
        while (!(hadc1.Instance->ISR & ADC_ISR_EOC));   // spin ~300 ns for conversion
        adc_raw_current = hadc1.Instance->DR & 0x0FFFu; // reading DR clears EOC
        g_current_A = (((float)adc_raw_current - current_zero_counts) / current_counts_per_amp)-1.2;

        // Kalman4 (4-state motor model) — runs every tick.
        // Voltage estimated from last-cycle PWM duty; 1-sample lag is negligible at 1 kHz.
        float kf4_v = (g_pwm_duty / 100.0f) * V_supply;
        if (motor_dir_inverted) kf4_v = -kf4_v;
        g_motor_voltage = kf4_v;
        // Qk = Qc*Ts + (A*Qc + Qc*A')*Ts^2/2 + A*Qc*A'*Ts^3/3  (full second-order expansion)
        // Qc[2][2]=sv2/L^2 only; A[:,2]=[0, N*Kt/J, -R/L, 0]'
        // Base coefficients (motor-param-dependent, sigma-independent) are reused by kf_exp[].
        float kf_Ts     = LOOP_DT;
        float kf_Ts2    = kf_Ts  * kf_Ts;
        float kf_Ts3    = kf_Ts2 * kf_Ts;
        float kf_inv_L2 = 1.0f / (motor_L * motor_L);
        float kf_RL     = motor_R_arm / motor_L;
        float kf_NKtJ   = (motor_N * motor_Kt) / motor_J_eq;
        float q22_base  = kf_inv_L2 * (kf_Ts  - kf_RL * kf_Ts2 + (kf_RL * kf_RL) * kf_Ts3 / 3.0f);
        float q12_base  = kf_inv_L2 * kf_NKtJ * (kf_Ts2 * 0.5f  - kf_RL * kf_Ts3 / 3.0f);
        float q11_base  = kf_inv_L2 * (kf_NKtJ * kf_NKtJ) * kf_Ts3 / 3.0f;

        my_kf4.Q_data[10] = kf4_sigma_v2 * q22_base;  // Q[2][2]
        my_kf4.Q_data[6]  = kf4_sigma_v2 * q12_base;  // Q[1][2]
        my_kf4.Q_data[9]  = kf4_sigma_v2 * q12_base;  // Q[2][1]
        my_kf4.Q_data[5]  = kf4_sigma_v2 * q11_base;  // Q[1][1]
        my_kf4.R_data[0]  = kf4_r_theta;

        float *kf4_st = Kalman4_Update(&my_kf4, my_encoder.position_rad, kf4_v);
        g_kf4_position  = kf4_st[0];
        g_kf4_velocity  = kf4_st[1];
        g_kf4_current   = kf4_st[2];
        g_kf4_tau_d_obs = kf4_st[3];

        // --- Kalman Experiment: update all 6 instances in parallel ---
        if (kalman_exp_enabled) {
            for (int n = 0; n < KF_EXP_COUNT; n++) {
                float sv = kf_exp_sigma_v2[n];
                kf_exp[n].Q_data[10] = sv * q22_base;
                kf_exp[n].Q_data[6]  = sv * q12_base;
                kf_exp[n].Q_data[9]  = sv * q12_base;
                kf_exp[n].Q_data[5]  = sv * q11_base;
                kf_exp[n].R_data[0]  = kf_exp_r_theta[n];
                float *st = Kalman4_Update(&kf_exp[n], my_encoder.position_rad, kf4_v);
                kf_exp_states[n][0]  = st[0];
                kf_exp_states[n][1]  = st[1];
                kf_exp_states[n][2]  = st[2];
                kf_exp_states[n][3]  = st[3];
            }
        }

        // Trajectory generation at 1 kHz — Modes 1 and 3, outputs to volatile globals for TIM7
        if (control_mode == MODE_TRAJ_FF || control_mode == MODE_CASCADE_CTRL) {
            if (traj_type == TRAJ_TRAPEZOID) {
                Trapezoid_Update(&my_trapezoid);
                g_traj_pos     = traj_start_pos + my_trapezoid.p_current;
                g_smooth_vel   = my_trapezoid.v_current;
                g_smooth_accel = my_trapezoid.a_current;
                g_jerk         = 0.0f;
                g_traj_active  = my_trapezoid.is_active;
            } else {
                SCurve_Update(&my_scurve);
                g_traj_pos     = traj_start_pos + my_scurve.p_current;
                g_smooth_vel   = my_scurve.v_current;
                g_smooth_accel = my_scurve.a_current;
                g_jerk         = my_scurve.j_current;
                g_traj_active  = my_scurve.is_active;
            }
        }

        static uint8_t inner_cnt = 0;
        if (++inner_cnt >= inner_loop_div) {
            inner_cnt = 0;
            loop_dt_inner = (float)inner_loop_div * LOOP_DT;

        float pwm_out = 0.0f;

        if (hard_stop_active || !pid_enabled) {
            // Hard stop OR PID disabled — reset vel PID integrator and hold zero
            Velocity_PID_Reset();
            Set_Motor_PWM(0.0f);

        } else {
            switch (control_mode) {

                // Mode 1: open-loop — trajectory velocity → RefFF → PWM, no feedback
                case MODE_TRAJ_FF: {
                    if (refff_enabled && V_supply > 0.1f) {
                        float v_ff = RefFF_Update(&my_refff, g_smooth_vel);
                        pwm_out    = v_ff / V_supply * 100.0f;
                    } else {
                        // Fallback: simple back-EMF scaling
                        pwm_out = (motor_Ke * g_smooth_vel) / V_supply * 100.0f;
                    }
                    if (pwm_out >  max_pwm) pwm_out =  max_pwm;
                    if (pwm_out < -max_pwm) pwm_out = -max_pwm;
                    Set_Motor_PWM(pwm_out);
                    break;
                }

                // Mode 3: TIM7 computes vel_command → velocity PID here
                case MODE_CASCADE_CTRL: {
                    float fb_vel    = use_kf4_vel ? g_kf4_velocity : my_encoder.velocity_rad_s;
                    float vel_error = vel_command - fb_vel;
                    vel_error_live  = vel_error;
                    pwm_out = Velocity_PID_Controller(vel_error);

                    // Model-based voltage feedforward: converts vel_command (rad/s)
                    // to an equivalent PWM% that pre-compensates motor dynamics.
                    if (refff_enabled && V_supply > 0.1f) {
                        float v_ff   = RefFF_Update(&my_refff, vel_command);
                        float pwm_ff = v_ff / V_supply * 100.0f;
                        pwm_out += pwm_ff;
                    }

                    // Disturbance feedforward: cancels Kalman4 tau_d estimate.
                    {
                        float v_ff_d = DistFF_Update(&my_distff, g_kf4_tau_d_obs);
                        g_distff_pwm = (V_supply > 0.1f) ? (v_ff_d / V_supply * 100.0f) : 0.0f;
                        if (distff_enabled) pwm_out += g_distff_pwm;
                    }

                    if (pwm_out >  max_pwm)        pwm_out =  max_pwm;
                    if (pwm_out < -max_pwm)        pwm_out = -max_pwm;
                    if (pwm_out >  voltage_sat_pct) pwm_out =  voltage_sat_pct;
                    if (pwm_out < -voltage_sat_pct) pwm_out = -voltage_sat_pct;
                    Set_Motor_PWM(pwm_out);
                    break;
                }

                // Mode 2: Position PID only — TIM7 writes pwm_command, apply it directly
                case MODE_POS_CTRL:
                    pwm_out = pwm_command;
                    if (pwm_out >  voltage_sat_pct) pwm_out =  voltage_sat_pct;
                    if (pwm_out < -voltage_sat_pct) pwm_out = -voltage_sat_pct;
                    Set_Motor_PWM(pwm_out);
                    break;

                // Mode 7: Kalman4 calibration — direct PWM, Kalman4 state in telemetry
                case MODE_KALMAN_CAL:
                    Set_Motor_PWM(pwm_command);
                    pwm_out = pwm_command;
                    // Repurpose telemetry channels for Kalman4 state comparison:
                    //  bytes  2- 5 : Kalman4 position estimate  (compare with bytes 18-21)
                    //  bytes  6- 9 : Kalman4 velocity estimate  (compare with bytes 22-25)
                    //  bytes 10-13 : Kalman4 current estimate   (model-only)
                    //  bytes 14-17 : Kalman4 τ_d estimate
                    //  bytes 18-21 : actual encoder position    (unchanged)
                    //  bytes 22-25 : actual raw velocity        (unchanged)
                    //  bytes 26-29 : Kalman4 velocity           (standard Kalman slot)
                    g_traj_pos     = g_kf4_position;
                    g_smooth_vel   = g_kf4_velocity;
                    g_smooth_accel = g_kf4_current;
                    g_jerk         = g_kf4_tau_d_obs;
                    break;

                default:
                    Set_Motor_PWM(0.0f);
                    break;
            }
        }

        g_pwm_duty = pwm_out;
        } /* end inner_loop_div gate */

        g_position_rad   = my_encoder.position_rad;
        g_velocity_rad_s = my_encoder.velocity_rad_s;

        if (kalman_exp_enabled) {
            if (!kf_exp_tx_pending) {
                Pack_KalmanExp_Telemetry();
                kf_exp_tx_pending = 1;
            }
        } else {
            if (!tx_pending) {
                Pack_Telemetry();
                tx_pending = 1;
            }
        }
        return;
    }

    // =========================================================================
    // TIM7 — 500 Hz OUTER LOOP: position PID + trajectory generation
    // =========================================================================
    if (htim->Instance != TIM7) return;

    // --- Full state reset ---
    if (reset_all) {
        reset_all = 0;
        // Re-init trajectory generators — zeros p_current, t_now, v/a/j_current, is_active
        SCurve_Init(&my_scurve, max_velocity, max_accel, max_jerk, TRAJ_DT);
        Trapezoid_Init(&my_trapezoid, max_velocity, max_accel, TRAJ_DT);
        traj_start_pos         = 0.0f;   // g_traj_pos = traj_start_pos + p_current = 0
        t_cruise_seg           = 0.0f;
        // Reset encoder position to zero
        __HAL_TIM_SET_COUNTER(&htim1, 0);
        Encoder_Init(&my_encoder, LOOP_DT);
        // Clear inter-loop commands
        vel_command            = 0.0f;
        pwm_command            = 0.0f;
        hard_stop_active       = 0;
        prev_traj_active_m3    = 0;
        // Reset all PID integrators and feedforward state
        Velocity_PID_Reset();
        Position_PID_Reset();
        RefFF_Init(&my_refff, motor_J_eq, motor_L, motor_R_arm, motor_b_eq,
                   motor_N, motor_Kt, motor_Ke, 0.02f, LOOP_DT);
        Kalman4_Init(&my_kf4, 0.0f, 0.0f, 0.0f, LOOP_DT,
                     motor_J_eq, motor_b_eq, motor_N, motor_Kt, motor_Ke,
                     motor_L, motor_R_arm, kf4_sigma_v2, kf4_r_theta);
        DistFF_Init(&my_distff, motor_L, motor_R_arm, motor_N, motor_Kt, distff_tau, LOOP_DT);
        g_distff_pwm = 0.0f;
        g_kf4_position  = 0.0f;
        g_kf4_velocity  = 0.0f;
        g_kf4_current   = 0.0f;
        g_kf4_tau_d_obs = 0.0f;
        kf_sine_phase          = 0.0f;
        // Clear telemetry and debug observables
        g_position_rad         = 0.0f;
        g_velocity_rad_s       = 0.0f;
        g_traj_pos             = 0.0f;
        g_smooth_vel           = 0.0f;
        g_smooth_accel         = 0.0f;
        g_jerk                 = 0.0f;
        g_pwm_duty             = 0.0f;
        ss_error_deg           = 0.0f;
        ss_error_rad           = 0.0f;
        vel_error_live         = 0.0f;
        i_term_live            = 0.0f;
        // Abort any running sequence or sweep
        seq_enabled            = 0;
        seq_index              = 0;
        seq_was_enabled        = 0;
        seq_step_done          = 0;
        seq_delay_counter      = 0;
        sweep_enabled          = 0;
        sweep_index            = 0;
        sweep_was_enabled      = 0;
        sweep_state            = 0;
        sweep_step_done        = 0;
        sweep_delay_counter    = 0;
        // Sync prev_target so auto-retrigger does not double-fire
        prev_traj_target_deg   = traj_target_deg;
        // Force mode-change handler to fire on the very next tick →
        // Start_Trajectory is called automatically toward current traj_target_deg
        prev_control_mode      = 0xFF;
        prev_traj_type         = 0xFF;
    }

    // --- Apply motor parameters without full reset (position not zeroed) ---
    if (apply_motor_params) {
        apply_motor_params = 0;
        RefFF_Init(&my_refff, motor_J_eq, motor_L, motor_R_arm, motor_b_eq,
                   motor_N, motor_Kt, motor_Ke, 0.02f, LOOP_DT);
        Kalman4_Init(&my_kf4,
                     g_kf4_position, g_kf4_velocity, g_kf4_current, LOOP_DT,
                     motor_J_eq, motor_b_eq, motor_N, motor_Kt, motor_Ke,
                     motor_L, motor_R_arm, kf4_sigma_v2, kf4_r_theta);
        DistFF_Init(&my_distff, motor_L, motor_R_arm, motor_N, motor_Kt, distff_tau, LOOP_DT);
        KalmanExp_Init();
    }

    // --- Zero encoder on demand ---
    if (zero_encoder) {
        zero_encoder = 0;
        __HAL_TIM_SET_COUNTER(&htim1, 0);
        Encoder_Init(&my_encoder, LOOP_DT);
        g_position_rad   = 0.0f;
        g_velocity_rad_s = 0.0f;
        vel_command      = 0.0f;
        pwm_command      = 0.0f;
        hard_stop_active = 0;
        prev_traj_active_m3 = 0;
        Position_PID_Reset();
        Velocity_PID_Reset();
        Kalman4_Reset(&my_kf4, 0.0f, 0.0f, 0.0f);
        g_kf4_position  = 0.0f;
        g_kf4_velocity  = 0.0f;
        g_kf4_current   = 0.0f;
        g_kf4_tau_d_obs = 0.0f;
    }

    // --- Mode / trajectory-type change ---
    if (control_mode != prev_control_mode || traj_type != prev_traj_type) {
        SCurve_Init(&my_scurve, max_velocity, max_accel, max_jerk, TRAJ_DT);
        Trapezoid_Init(&my_trapezoid, max_velocity, max_accel, TRAJ_DT);
        Velocity_PID_Reset();
        Position_PID_Reset();
        vel_command         = 0.0f;
        pwm_command         = 0.0f;
        hard_stop_active    = 0;
        prev_traj_active_m3 = 0;
        Kalman4_Reset(&my_kf4, my_encoder.position_rad, 0.0f, 0.0f);
        prev_control_mode   = control_mode;
        prev_traj_type      = traj_type;
        if (control_mode == MODE_CASCADE_CTRL || control_mode == MODE_TRAJ_FF) {
            float disp = traj_target_deg * DEG_TO_RAD - my_encoder.position_rad;
            Start_Trajectory(disp);
        }
    }

    // --- Sequence mode ---
    // Rising edge: load step 0; auto-retrigger below starts the trajectory.
    // Settled state: counts down seq_step_delay before loading the next target.
    if (seq_enabled && !seq_was_enabled) {
        if (seq_count >= 1 && seq_count <= 9) {
            seq_index         = 0;
            seq_step_done     = 0;
            seq_delay_counter = 0;
            traj_target_deg   = seq_targets[0];
        } else {
            seq_enabled = 0;
        }
    } else if (seq_enabled) {
        if (!seq_step_done) {
            // Waiting for trajectory to finish and position to settle
            uint8_t traj_done    = (traj_type == TRAJ_TRAPEZOID) ? !my_trapezoid.is_active
                                                                  : !my_scurve.is_active;
            float   deadband_rad = pos_deadband_deg * DEG_TO_RAD;
            float   pos_err      = fabsf(my_encoder.position_rad - seq_targets[seq_index] * DEG_TO_RAD);
            if (traj_done && pos_err <= deadband_rad) {
                seq_step_done     = 1;
                seq_delay_counter = (uint32_t)(seq_step_delay / POS_DT);
            }
        } else {
            // Step settled — count down inter-step delay then advance
            if (seq_delay_counter > 0) {
                seq_delay_counter--;
            } else {
                seq_step_done = 0;
                seq_index++;
                if (seq_index >= seq_count) {
                    seq_enabled = 0;   // sequence complete
                } else {
                    traj_target_deg = seq_targets[seq_index];
                }
            }
        }
    }
    seq_was_enabled = seq_enabled;

    // --- Sweep mode: 0 → target → 0 → (target+step) → ... → 0 → stop ---
    if (sweep_enabled && !sweep_was_enabled) {
        sweep_index       = 0;
        sweep_state       = 0;
        sweep_step_done   = 0;
        sweep_delay_counter = 0;
        traj_target_deg   = sweep_start_deg + sweep_index * sweep_step_deg;
        hard_stop_active  = 0;
    } else if (sweep_enabled) {
        if (!sweep_step_done) {
            // Wait for: trajectory done + position in deadband + motor truly stopped.
            // Velocity check mirrors the hard-stop condition so dwell only starts
            // after the arm has physically settled, not just entered the deadband
            // while still moving (which would restart on the other side).
            uint8_t traj_done    = !g_traj_active;
            float   deadband_rad = pos_deadband_deg * DEG_TO_RAD;
            float   expected_rad = traj_target_deg * DEG_TO_RAD;
            float   fb_vel_sw    = use_kf4_vel ? g_kf4_velocity : my_encoder.velocity_rad_s;
            uint8_t pos_ok       = (fabsf(my_encoder.position_rad - expected_rad) <= deadband_rad);
            uint8_t vel_ok       = (fabsf(fb_vel_sw) < vel_deadband_rad_s);
            if (traj_done && pos_ok && vel_ok) {
                sweep_step_done     = 1;
                sweep_delay_counter = (uint32_t)(sweep_delay_s / POS_DT);
            }
        } else {
            if (sweep_delay_counter > 0) {
                sweep_delay_counter--;
            } else {
                sweep_step_done = 0;
                if (sweep_state == 0) {
                    // Settled at target — check if done, else go to zero
                    float current_target = sweep_start_deg + sweep_index * sweep_step_deg;
                    if (current_target >= sweep_stop_deg) {
                        sweep_enabled = 0;
                    } else {
                        sweep_state     = 1;
                        traj_target_deg = 0.0f;
                        hard_stop_active = 0;
                    }
                } else {
                    // Settled at zero — advance to next target
                    sweep_index++;
                    float next = sweep_start_deg + sweep_index * sweep_step_deg;
                    if (next > sweep_stop_deg) next = sweep_stop_deg;
                    traj_target_deg  = next;
                    hard_stop_active = 0;
                    sweep_state      = 0;
                }
            }
        }
    }
    sweep_was_enabled = sweep_enabled;

    // --- Auto-retrigger when target position changes ---
    if (traj_target_deg != prev_traj_target_deg) {
        prev_traj_target_deg = traj_target_deg;
        hard_stop_active = 0;
        if (control_mode == MODE_CASCADE_CTRL) {
            float disp = traj_target_deg * DEG_TO_RAD - my_encoder.position_rad;
            Start_Trajectory(disp);
        }
    }

    // --- Manual retrigger ---
    if (start_move) {
        start_move       = 0;
        hard_stop_active = 0;
        float disp = traj_target_deg * DEG_TO_RAD - my_encoder.position_rad;
        Start_Trajectory(disp);
    }

    // --- pid_enabled rising edge: cancel any stale trajectory so motor stays still ---
    if (pid_enabled && !prev_pid_enabled) {
        SCurve_Init(&my_scurve, max_velocity, max_accel, max_jerk, TRAJ_DT);
        Trapezoid_Init(&my_trapezoid, max_velocity, max_accel, TRAJ_DT);
        traj_start_pos      = my_encoder.position_rad;
        prev_traj_active_m3 = 0;
        Velocity_PID_Reset();
        Position_PID_Reset();
        DistFF_Reset(&my_distff);
        g_distff_pwm = 0.0f;
    }
    prev_pid_enabled = pid_enabled;

    // --- PID master enable gate ---
    if (!pid_enabled) {
        vel_command      = 0.0f;
        pwm_command      = 0.0f;
        hard_stop_active = 0;
        Position_PID_Reset();
        return;   // skip trajectory advance and position PID entirely
    }

    static uint8_t outer_cnt = 0;
    if (++outer_cnt >= outer_loop_div) {
        outer_cnt = 0;
        loop_dt_outer = (float)outer_loop_div * POS_DT;

    switch (control_mode) {

        case MODE_TRAJ_FF: {
            // Open-loop: trajectory runs via retrigger logic above.
            // TIM6 converts g_smooth_vel → PWM via RefFF; no position or velocity PID.
            // Motor naturally decelerates to 0 when trajectory ends (g_smooth_vel → 0).
            vel_command      = 0.0f;
            hard_stop_active = 0;
            break;
        }

        case MODE_POS_CTRL: {
            // Position PID → PWM directly.  No trajectory, no velocity inner loop.
            // Reference = pos_ctrl_target_deg (single degree value, set in Live Expressions).
            float ref_rad = pos_ctrl_target_deg * DEG_TO_RAD;
            g_traj_pos   = ref_rad;   // feed into telemetry so Simulink shows reference

            float pos_error = ref_rad - my_encoder.position_rad;
            ss_error_rad = pos_error;
            ss_error_deg = pos_error * (180.0f / 3.14159265f);
            ss_reached = (fabsf(ss_error_deg) <= pos_deadband_deg) ? 1u : 0u;

            float fb_vel  = use_kf4_vel ? g_kf4_velocity : my_encoder.velocity_rad_s;
            float pwm_raw = Position_PID_Controller(pos_error, fb_vel);
            if (pwm_raw >  max_pwm) pwm_raw =  max_pwm;
            if (pwm_raw < -max_pwm) pwm_raw = -max_pwm;

            uint8_t vel_settled = (fabsf(fb_vel) < vel_deadband_rad_s) ? 1u : 0u;
            if (ss_reached && vel_settled) {
                ss_final_error_deg = ss_error_deg;
                pwm_command      = 0.0f;
                hard_stop_active = 1;
            } else {
                hard_stop_active = 0;
                pwm_command      = pwm_raw;
            }
            vel_command = 0.0f;
            break;
        }

        case MODE_CASCADE_CTRL: {
            // Trajectory globals (g_traj_pos, g_smooth_vel, g_traj_active) are updated
            // by TIM6 at 1 kHz — read them here for position PID at 500 Hz.
            uint8_t traj_active = g_traj_active;

            if (prev_traj_active_m3 && !traj_active) {
                Velocity_PID_Reset();
                Position_PID_Reset();
            }
            prev_traj_active_m3 = traj_active;

            float pos_error = g_traj_pos - my_encoder.position_rad;
            ss_error_rad = pos_error;
            ss_error_deg = pos_error * (180.0f / 3.14159265f);
            ss_reached = (fabsf(ss_error_deg) <= pos_deadband_deg) ? 1u : 0u;

            float fb_vel_pos  = use_kf4_vel ? g_kf4_velocity : my_encoder.velocity_rad_s;
            float vel_correct = Position_PID_Controller(pos_error, fb_vel_pos);
            if (vel_correct >  max_velocity) vel_correct =  max_velocity;
            if (vel_correct < -max_velocity) vel_correct = -max_velocity;

            uint8_t vel_settled = (fabsf(fb_vel_pos) < vel_deadband_rad_s) ? 1u : 0u;
            if (!traj_active && ss_reached && vel_settled) {
                // Position AND velocity both within deadband — safe to cut motor
                ss_final_error_deg = ss_error_deg;
                vel_command      = 0.0f;
                hard_stop_active = 1;
            } else {
                // Non-sticky: PID resumes if motor drifts back outside deadband
                hard_stop_active = 0;
                float vel_cmd = g_smooth_vel + vel_correct;
                if (vel_cmd >  max_velocity)   vel_cmd =  max_velocity;
                if (vel_cmd < -max_velocity)   vel_cmd = -max_velocity;
                if (vel_cmd >  vel_sat_rad_s)  vel_cmd =  vel_sat_rad_s;
                if (vel_cmd < -vel_sat_rad_s)  vel_cmd = -vel_sat_rad_s;
                vel_command = vel_cmd;
            }
            break;
        }

        // Mode 7: Kalman4 calibration — direct PWM or sine excitation signal
        case MODE_KALMAN_CAL: {
            float cal_out;
            if (kf_sine_enabled) {
                // Advance phase accumulator: Δφ = 2π × freq × POS_DT
                kf_sine_phase += 2.0f * 3.14159265f * kf_sine_freq * POS_DT;
                if (kf_sine_phase >= 2.0f * 3.14159265f)
                    kf_sine_phase -= 2.0f * 3.14159265f;
                // kf_cal_pwm = DC offset, kf_sine_dir = +1 normal / -1 reversed
                cal_out = kf_cal_pwm + kf_sine_dir * kf_sine_amp * sinf(kf_sine_phase);
                if (cal_out >  100.0f) cal_out =  100.0f;
                if (cal_out < -100.0f) cal_out = -100.0f;
            } else {
                kf_sine_phase = 0.0f;   // reset phase when sine is off
                cal_out = kf_cal_pwm;
            }
            pwm_command      = cal_out;
            vel_command      = 0.0f;
            hard_stop_active = 0;
            g_traj_pos     = 0.0f;
            g_smooth_vel   = 0.0f;
            g_smooth_accel = 0.0f;
            g_jerk         = 0.0f;
            break;
        }

        default:
            vel_command      = 0.0f;
            pwm_command      = 0.0f;
            hard_stop_active = 1;
            break;
    }
    } /* end outer_loop_div gate */
}

/* USER CODE END 4 */

void Error_Handler(void)
{
  __disable_irq();
  while (1)
  {
  }
}
